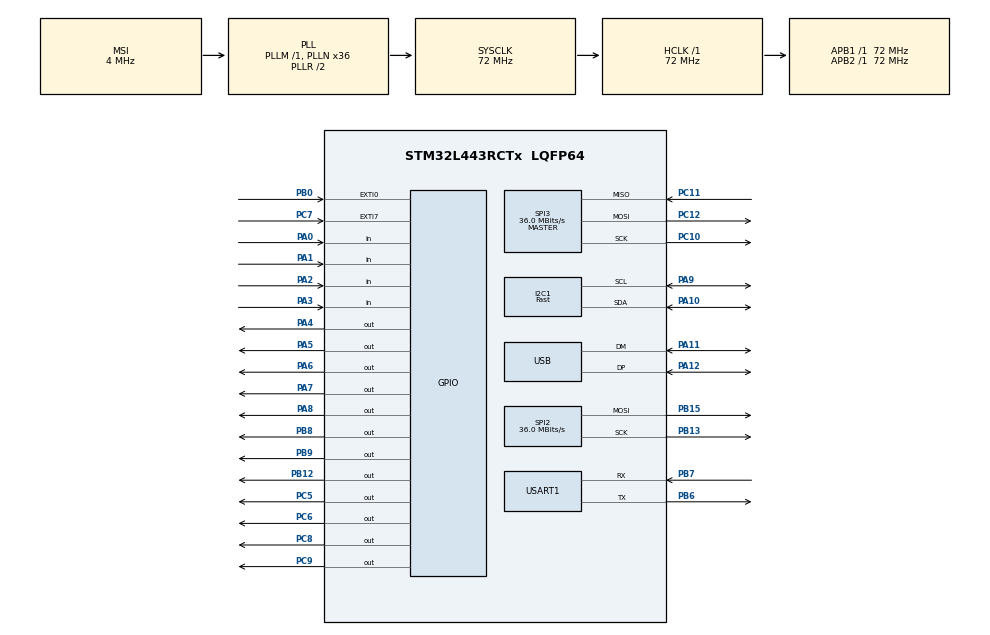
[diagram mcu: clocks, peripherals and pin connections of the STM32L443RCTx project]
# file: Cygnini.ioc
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FREERTOS.Tasks01=defaultTask,24,128,StartDefaultTask,Default,NULL,Dynamic,NULL,NULL
FREERTOS.configTOTAL_HEAP_SIZE=40000
FREERTOS.configUSE_IDLE_HOOK=1
I2C1.I2C_Speed_Mode=I2C_Fast
I2C1.Timing=0x00702681
Mcu.Family=STM32L4
Mcu.Name=STM32L443RCTx
Mcu.Package=LQFP64
NVIC.PriorityGroup=NVIC_PRIORITYGROUP_4
NVIC.TIM1_UP_TIM16_IRQn=true\:0\:0\:false\:false\:true\:false\:false\:true
NVIC.TimeBase=TIM1_UP_TIM16_IRQn
NVIC.TimeBaseIP=TIM1
NVIC.USB_IRQn=true\:5\:0\:false\:false\:true\:true\:false\:true
PA0.Signal=GPIO_Input
PA1.Signal=GPIO_Input
PA10.Mode=I2C
PA10.Signal=I2C1_SDA
PA11.Mode=Device
PA11.Signal=USB_DM
PA12.Mode=Device
PA12.Signal=USB_DP
PA13\ (JTMS-SWDIO).Mode=Serial_Wire
PA13\ (JTMS-SWDIO).Signal=SYS_JTMS-SWDIO
PA14\ (JTCK-SWCLK).Mode=Serial_Wire
PA14\ (JTCK-SWCLK).Signal=SYS_JTCK-SWCLK
PA2.Signal=GPIO_Input
PA3.Signal=GPIO_Input
PA4.Signal=GPIO_Output
PA5.Signal=GPIO_Output
PA6.Signal=GPIO_Output
PA7.Signal=GPIO_Output
PA8.Signal=GPIO_Output
PA9.Mode=I2C
PA9.Signal=I2C1_SCL
PB0.Signal=GPXTI0
PB12.Signal=GPIO_Output
PB13.Mode=TX_Only_Simplex_Unidirect_Master
PB13.Signal=SPI2_SCK
PB15.Mode=TX_Only_Simplex_Unidirect_Master
PB15.Signal=SPI2_MOSI
PB3\ (JTDO-TRACESWO).Signal=SYS_JTDO-SWO
PB6.Mode=Asynchronous
PB6.Signal=USART1_TX
PB7.Mode=Asynchronous
PB7.Signal=USART1_RX
PB8.Signal=GPIO_Output
PB9.Signal=GPIO_Output
PC10.Mode=Full_Duplex_Master
PC10.Signal=SPI3_SCK
PC11.Mode=Full_Duplex_Master
PC11.Signal=SPI3_MISO
PC12.Mode=Full_Duplex_Master
PC12.Signal=SPI3_MOSI
PC14-OSC32_IN\ (PC14).Mode=LSE-External-Oscillator
PC14-OSC32_IN\ (PC14).Signal=RCC_OSC32_IN
PC15-OSC32_OUT\ (PC15).Mode=LSE-External-Oscillator
PC15-OSC32_OUT\ (PC15).Signal=RCC_OSC32_OUT
PC5.Signal=GPIO_Output
PC6.Signal=GPIO_Output
PC7.Signal=GPXTI7
PC8.Signal=GPIO_Output
PC9.Signal=GPIO_Output
ProjectManager.HeapSize=0x200
ProjectManager.StackSize=0x400
ProjectManager.TargetToolchain=STM32CubeIDE
RCC.ADCFreq_Value=48000000
RCC.AHBFreq_Value=72000000
RCC.APB1Freq_Value=72000000
RCC.APB1TimFreq_Value=72000000
RCC.APB2Freq_Value=72000000
RCC.APB2TimFreq_Value=72000000
RCC.CortexFreq_Value=72000000
RCC.HCLKFreq_Value=72000000
RCC.HSE_VALUE=8000000
RCC.HSI48_VALUE=48000000
RCC.HSI_VALUE=16000000
RCC.MSI_VALUE=4000000
RCC.PLLN=36
RCC.PLLSAI1N=24
RCC.SYSCLKFreq_VALUE=72000000
RCC.SYSCLKSource=RCC_SYSCLKSOURCE_PLLCLK
RCC.USBFreq_Value=48000000
RCC.VCOOutputFreq_Value=144000000
SPI2.BaudRatePrescaler=SPI_BAUDRATEPRESCALER_2
SPI2.CalculateBaudRate=36.0 MBits/s
SPI2.DataSize=SPI_DATASIZE_8BIT
SPI2.Direction=SPI_DIRECTION_2LINES
SPI2.Mode=SPI_MODE_MASTER
SPI2.VirtualType=VM_MASTER
SPI3.BaudRatePrescaler=SPI_BAUDRATEPRESCALER_2
SPI3.CalculateBaudRate=36.0 MBits/s
SPI3.DataSize=SPI_DATASIZE_8BIT
SPI3.Direction=SPI_DIRECTION_2LINES
SPI3.Mode=SPI_MODE_MASTER
SPI3.VirtualType=VM_MASTER
USART1.VirtualMode-Asynchronous=VM_ASYNC
USB_DEVICE.CLASS_NAME_FS=CDC
USB_DEVICE.VirtualMode=Cdc
USB_DEVICE.VirtualModeFS=Cdc_FS
VP_FREERTOS_VS_CMSIS_V2.Mode=CMSIS_V2
VP_SYS_VS_tim1.Mode=TIM1
VP_USB_DEVICE_VS_USB_DEVICE_CDC_FS.Mode=CDC_FS
board=custom

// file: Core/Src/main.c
/* USER CODE BEGIN Header */
/**
  ******************************************************************************
  * @file           : main.c
  * @brief          : Main program body
  ******************************************************************************
  * @attention
  *
  * <h2><center>&copy; Copyright (c) 2020 STMicroelectronics.
  * All rights reserved.</center></h2>
  *
  * This software component is licensed by ST under BSD 3-Clause license,
  * the "License"; You may not use this file except in compliance with the
  * License. You may obtain a copy of the License at:
  *                        opensource.org/licenses/BSD-3-Clause
  *
  ******************************************************************************
  */
/* USER CODE END Header */

#include "main.h"
#include "cmsis_os.h"
#include "usb_device.h"

/* USER CODE BEGIN Includes */
#include "cygnini.h"
/* USER CODE END Includes */

I2C_HandleTypeDef hi2c1;

SPI_HandleTypeDef hspi2;
SPI_HandleTypeDef hspi3;

UART_HandleTypeDef huart1;

/* Definitions for defaultTask */
osThreadId_t defaultTaskHandle;
const osThreadAttr_t defaultTask_attributes = {
  .name = "defaultTask",
  .priority = (osPriority_t) osPriorityNormal,
  .stack_size = 128 * 4
};

void SystemClock_Config(void);
static void MX_GPIO_Init(void);
static void MX_SPI2_Init(void);
static void MX_SPI3_Init(void);
static void MX_USART1_UART_Init(void);
static void MX_I2C1_Init(void);
void StartDefaultTask(void *argument);

int main(void)
{

  /* MCU Configuration--------------------------------------------------------*/

  /* Reset of all peripherals, Initializes the Flash interface and the Systick. */
  HAL_Init();

  /* Configure the system clock */
  SystemClock_Config();

  /* Initialize all configured peripherals */
  MX_GPIO_Init();
  MX_SPI2_Init();
  MX_SPI3_Init();
  MX_USART1_UART_Init();
  MX_I2C1_Init();
  /* USER CODE BEGIN 2 */
  cygnini();
  return 0;
  /* USER CODE END 2 */

  /* Init scheduler */
  osKernelInitialize();

  /* Create the thread(s) */
  /* creation of defaultTask */
  defaultTaskHandle = osThreadNew(StartDefaultTask, NULL, &defaultTask_attributes);

  /* Start scheduler */
  osKernelStart();

  /* We should never get here as control is now taken by the scheduler */
  /* Infinite loop */
  while (1)
  {

  }
}

void SystemClock_Config(void)
{
  RCC_OscInitTypeDef RCC_OscInitStruct = {0};
  RCC_ClkInitTypeDef RCC_ClkInitStruct = {0};
  RCC_PeriphCLKInitTypeDef PeriphClkInit = {0};

  /** Configure LSE Drive Capability
  */
  HAL_PWR_EnableBkUpAccess();
  __HAL_RCC_LSEDRIVE_CONFIG(RCC_LSEDRIVE_LOW);
  /** Initializes the CPU, AHB and APB busses clocks
  */
  RCC_OscInitStruct.OscillatorType = RCC_OSCILLATORTYPE_LSE|RCC_OSCILLATORTYPE_MSI;
  RCC_OscInitStruct.LSEState = RCC_LSE_ON;
  RCC_OscInitStruct.MSIState = RCC_MSI_ON;
  RCC_OscInitStruct.MSICalibrationValue = 0;
  RCC_OscInitStruct.MSIClockRange = RCC_MSIRANGE_6;
  RCC_OscInitStruct.PLL.PLLState = RCC_PLL_ON;
  RCC_OscInitStruct.PLL.PLLSource = RCC_PLLSOURCE_MSI;
  RCC_OscInitStruct.PLL.PLLM = 1;
  RCC_OscInitStruct.PLL.PLLN = 36;
  RCC_OscInitStruct.PLL.PLLP = RCC_PLLP_DIV7;
  RCC_OscInitStruct.PLL.PLLQ = RCC_PLLQ_DIV2;
  RCC_OscInitStruct.PLL.PLLR = RCC_PLLR_DIV2;
  if (HAL_RCC_OscConfig(&RCC_OscInitStruct) != HAL_OK)
  {
    Error_Handler();
  }
  /** Initializes the CPU, AHB and APB busses clocks
  */
  RCC_ClkInitStruct.ClockType = RCC_CLOCKTYPE_HCLK|RCC_CLOCKTYPE_SYSCLK
                              |RCC_CLOCKTYPE_PCLK1|RCC_CLOCKTYPE_PCLK2;
  RCC_ClkInitStruct.SYSCLKSource = RCC_SYSCLKSOURCE_PLLCLK;
  RCC_ClkInitStruct.AHBCLKDivider = RCC_SYSCLK_DIV1;
  RCC_ClkInitStruct.APB1CLKDivider = RCC_HCLK_DIV1;
  RCC_ClkInitStruct.APB2CLKDivider = RCC_HCLK_DIV1;

  if (HAL_RCC_ClockConfig(&RCC_ClkInitStruct, FLASH_LATENCY_4) != HAL_OK)
  {
    Error_Handler();
  }
  PeriphClkInit.PeriphClockSelection = RCC_PERIPHCLK_USART1|RCC_PERIPHCLK_I2C1
                              |RCC_PERIPHCLK_USB;
  PeriphClkInit.Usart1ClockSelection = RCC_USART1CLKSOURCE_PCLK2;
  PeriphClkInit.I2c1ClockSelection = RCC_I2C1CLKSOURCE_PCLK1;
  PeriphClkInit.UsbClockSelection = RCC_USBCLKSOURCE_PLLSAI1;
  PeriphClkInit.PLLSAI1.PLLSAI1Source = RCC_PLLSOURCE_MSI;
  PeriphClkInit.PLLSAI1.PLLSAI1M = 1;
  PeriphClkInit.PLLSAI1.PLLSAI1N = 24;
  PeriphClkInit.PLLSAI1.PLLSAI1P = RCC_PLLP_DIV7;
  PeriphClkInit.PLLSAI1.PLLSAI1Q = RCC_PLLQ_DIV2;
  PeriphClkInit.PLLSAI1.PLLSAI1R = RCC_PLLR_DIV2;
  PeriphClkInit.PLLSAI1.PLLSAI1ClockOut = RCC_PLLSAI1_48M2CLK;
  if (HAL_RCCEx_PeriphCLKConfig(&PeriphClkInit) != HAL_OK)
  {
    Error_Handler();
  }
  /** Configure the main internal regulator output voltage
  */
  if (HAL_PWREx_ControlVoltageScaling(PWR_REGULATOR_VOLTAGE_SCALE1) != HAL_OK)
  {
    Error_Handler();
  }
  /** Enable MSI Auto calibration
  */
  HAL_RCCEx_EnableMSIPLLMode();
}

static void MX_I2C1_Init(void)
{

  hi2c1.Instance = I2C1;
  hi2c1.Init.Timing = 0x00702681;
  hi2c1.Init.OwnAddress1 = 0;
  hi2c1.Init.AddressingMode = I2C_ADDRESSINGMODE_7BIT;
  hi2c1.Init.DualAddressMode = I2C_DUALADDRESS_DISABLE;
  hi2c1.Init.OwnAddress2 = 0;
  hi2c1.Init.OwnAddress2Masks = I2C_OA2_NOMASK;
  hi2c1.Init.GeneralCallMode = I2C_GENERALCALL_DISABLE;
  hi2c1.Init.NoStretchMode = I2C_NOSTRETCH_DISABLE;
  if (HAL_I2C_Init(&hi2c1) != HAL_OK)
  {
    Error_Handler();
  }
  /** Configure Analogue filter
  */
  if (HAL_I2CEx_ConfigAnalogFilter(&hi2c1, I2C_ANALOGFILTER_ENABLE) != HAL_OK)
  {
    Error_Handler();
  }
  /** Configure Digital filter
  */
  if (HAL_I2CEx_ConfigDigitalFilter(&hi2c1, 0) != HAL_OK)
  {
    Error_Handler();
  }

}

static void MX_SPI2_Init(void)
{

  /* SPI2 parameter configuration*/
  hspi2.Instance = SPI2;
  hspi2.Init.Mode = SPI_MODE_MASTER;
  hspi2.Init.Direction = SPI_DIRECTION_2LINES;
  hspi2.Init.DataSize = SPI_DATASIZE_8BIT;
  hspi2.Init.CLKPolarity = SPI_POLARITY_LOW;
  hspi2.Init.CLKPhase = SPI_PHASE_1EDGE;
  hspi2.Init.NSS = SPI_NSS_SOFT;
  hspi2.Init.BaudRatePrescaler = SPI_BAUDRATEPRESCALER_2;
  hspi2.Init.FirstBit = SPI_FIRSTBIT_MSB;
  hspi2.Init.TIMode = SPI_TIMODE_DISABLE;
  hspi2.Init.CRCCalculation = SPI_CRCCALCULATION_DISABLE;
  hspi2.Init.CRCPolynomial = 7;
  hspi2.Init.CRCLength = SPI_CRC_LENGTH_DATASIZE;
  hspi2.Init.NSSPMode = SPI_NSS_PULSE_ENABLE;
  if (HAL_SPI_Init(&hspi2) != HAL_OK)
  {
    Error_Handler();
  }

}

static void MX_SPI3_Init(void)
{

  /* SPI3 parameter configuration*/
  hspi3.Instance = SPI3;
  hspi3.Init.Mode = SPI_MODE_MASTER;
  hspi3.Init.Direction = SPI_DIRECTION_2LINES;
  hspi3.Init.DataSize = SPI_DATASIZE_8BIT;
  hspi3.Init.CLKPolarity = SPI_POLARITY_LOW;
  hspi3.Init.CLKPhase = SPI_PHASE_1EDGE;
  hspi3.Init.NSS = SPI_NSS_SOFT;
  hspi3.Init.BaudRatePrescaler = SPI_BAUDRATEPRESCALER_2;
  hspi3.Init.FirstBit = SPI_FIRSTBIT_MSB;
  hspi3.Init.TIMode = SPI_TIMODE_DISABLE;
  hspi3.Init.CRCCalculation = SPI_CRCCALCULATION_DISABLE;
  hspi3.Init.CRCPolynomial = 7;
  hspi3.Init.CRCLength = SPI_CRC_LENGTH_DATASIZE;
  hspi3.Init.NSSPMode = SPI_NSS_PULSE_ENABLE;
  if (HAL_SPI_Init(&hspi3) != HAL_OK)
  {
    Error_Handler();
  }

}

static void MX_USART1_UART_Init(void)
{

  huart1.Instance = USART1;
  huart1.Init.BaudRate = 115200;
  huart1.Init.WordLength = UART_WORDLENGTH_8B;
  huart1.Init.StopBits = UART_STOPBITS_1;
  huart1.Init.Parity = UART_PARITY_NONE;
  huart1.Init.Mode = UART_MODE_TX_RX;
  huart1.Init.HwFlowCtl = UART_HWCONTROL_NONE;
  huart1.Init.OverSampling = UART_OVERSAMPLING_16;
  huart1.Init.OneBitSampling = UART_ONE_BIT_SAMPLE_DISABLE;
  huart1.AdvancedInit.AdvFeatureInit = UART_ADVFEATURE_NO_INIT;
  if (HAL_UART_Init(&huart1) != HAL_OK)
  {
    Error_Handler();
  }

}

static void MX_GPIO_Init(void)
{
  GPIO_InitTypeDef GPIO_InitStruct = {0};

  /* GPIO Ports Clock Enable */
  __HAL_RCC_GPIOC_CLK_ENABLE();
  __HAL_RCC_GPIOA_CLK_ENABLE();
  __HAL_RCC_GPIOB_CLK_ENABLE();

  /*Configure GPIO pin Output Level */
  HAL_GPIO_WritePin(GPIOA, GPIO_PIN_4|GPIO_PIN_5|GPIO_PIN_6|GPIO_PIN_7
                          |GPIO_PIN_8, GPIO_PIN_RESET);

  /*Configure GPIO pin Output Level */
  HAL_GPIO_WritePin(GPIOC, GPIO_PIN_5|GPIO_PIN_6|GPIO_PIN_8|GPIO_PIN_9, GPIO_PIN_RESET);

  /*Configure GPIO pin Output Level */
  HAL_GPIO_WritePin(GPIOB, GPIO_PIN_12|GPIO_PIN_8|GPIO_PIN_9, GPIO_PIN_RESET);

  /*Configure GPIO pins : PA0 PA1 PA2 PA3 */
  GPIO_InitStruct.Pin = GPIO_PIN_0|GPIO_PIN_1|GPIO_PIN_2|GPIO_PIN_3;
  GPIO_InitStruct.Mode = GPIO_MODE_INPUT;
  GPIO_InitStruct.Pull = GPIO_NOPULL;
  HAL_GPIO_Init(GPIOA, &GPIO_InitStruct);

  /*Configure GPIO pins : PA4 PA5 PA6 PA7
                           PA8 */
  GPIO_InitStruct.Pin = GPIO_PIN_4|GPIO_PIN_5|GPIO_PIN_6|GPIO_PIN_7
                          |GPIO_PIN_8;
  GPIO_InitStruct.Mode = GPIO_MODE_OUTPUT_PP;
  GPIO_InitStruct.Pull = GPIO_NOPULL;
  GPIO_InitStruct.Speed = GPIO_SPEED_FREQ_LOW;
  HAL_GPIO_Init(GPIOA, &GPIO_InitStruct);

  /*Configure GPIO pins : PC5 PC6 PC8 PC9 */
  GPIO_InitStruct.Pin = GPIO_PIN_5|GPIO_PIN_6|GPIO_PIN_8|GPIO_PIN_9;
  GPIO_InitStruct.Mode = GPIO_MODE_OUTPUT_PP;
  GPIO_InitStruct.Pull = GPIO_NOPULL;
  GPIO_InitStruct.Speed = GPIO_SPEED_FREQ_LOW;
  HAL_GPIO_Init(GPIOC, &GPIO_InitStruct);

  /*Configure GPIO pin : PB0 */
  GPIO_InitStruct.Pin = GPIO_PIN_0;
  GPIO_InitStruct.Mode = GPIO_MODE_IT_RISING;
  GPIO_InitStruct.Pull = GPIO_NOPULL;
  HAL_GPIO_Init(GPIOB, &GPIO_InitStruct);

  /*Configure GPIO pins : PB12 PB8 PB9 */
  GPIO_InitStruct.Pin = GPIO_PIN_12|GPIO_PIN_8|GPIO_PIN_9;
  GPIO_InitStruct.Mode = GPIO_MODE_OUTPUT_PP;
  GPIO_InitStruct.Pull = GPIO_NOPULL;
  GPIO_InitStruct.Speed = GPIO_SPEED_FREQ_LOW;
  HAL_GPIO_Init(GPIOB, &GPIO_InitStruct);

  /*Configure GPIO pin : PC7 */
  GPIO_InitStruct.Pin = GPIO_PIN_7;
  GPIO_InitStruct.Mode = GPIO_MODE_IT_RISING;
  GPIO_InitStruct.Pull = GPIO_NOPULL;
  HAL_GPIO_Init(GPIOC, &GPIO_InitStruct);

}

void StartDefaultTask(void *argument)
{
  /* init code for USB_DEVICE */
  MX_USB_DEVICE_Init();
  /* USER CODE BEGIN 5 */
  /* Infinite loop */
  for(;;)
  {
    osDelay(1000);
    HAL_GPIO_WritePin (GPIOA, GPIO_PIN_8, GPIO_PIN_SET);
    osDelay(1000);
    HAL_GPIO_WritePin (GPIOA, GPIO_PIN_8, GPIO_PIN_RESET);
  }
  /* USER CODE END 5 */
}

 /**
  * @brief  Period elapsed callback in non blocking mode
  * @note   This function is called  when TIM1 interrupt took place, inside
  * HAL_TIM_IRQHandler(). It makes a direct call to HAL_IncTick() to increment
  * a global variable "uwTick" used as application time base.
  * @param  htim : TIM handle
  * @retval None
  */
void HAL_TIM_PeriodElapsedCallback(TIM_HandleTypeDef *htim)
{
  if (htim->Instance == TIM1) {
    HAL_IncTick();
  }
}

void Error_Handler(void)
{
}

/************************ (C) COPYRIGHT STMicroelectronics *****END OF FILE****/
